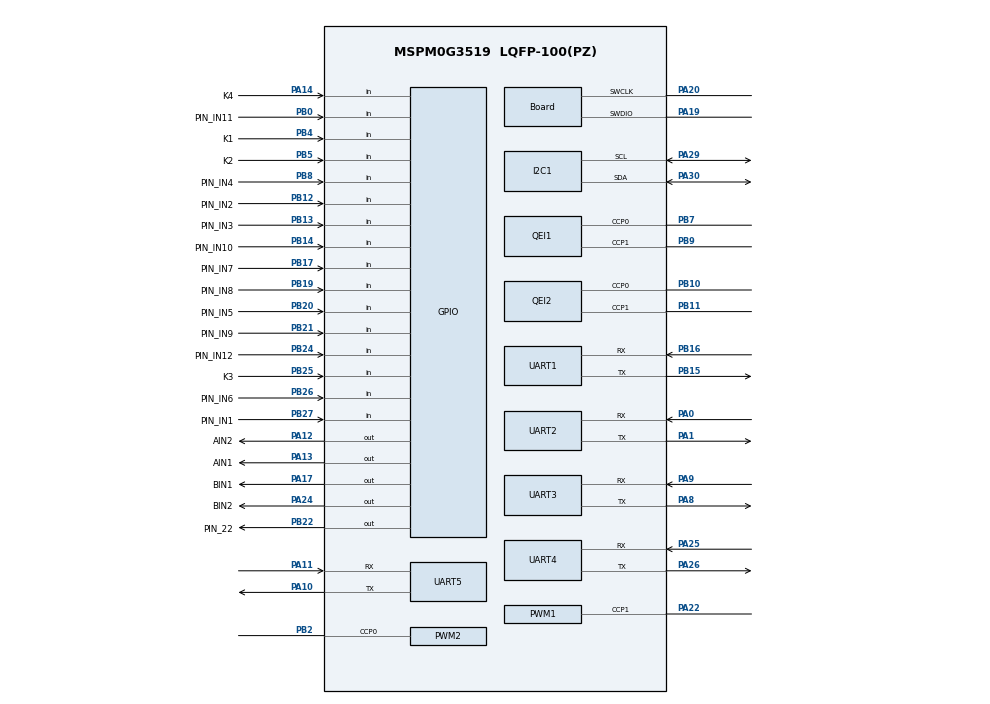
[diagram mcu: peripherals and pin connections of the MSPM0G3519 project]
/**
 * These arguments were used when this file was generated. They will be automatically applied on subsequent loads
 * via the GUI or CLI. Run CLI with '--help' for additional information on how to override these arguments.
 * @cliArgs --device "MSPM0G351X" --part "Default" --package "LQFP-100(PZ)" --product "mspm0_sdk@2.11.00.07"
 * @v2CliArgs --device "MSPM0G3519" --package "LQFP-100(PZ)" --product "mspm0_sdk@2.11.00.07"
 * @versions {"tool":"1.26.2+4477"}
 */

/**
 * Import the modules used in this configuration.
 */
const DMA    = scripting.addModule("/ti/driverlib/DMA");
const GPIO   = scripting.addModule("/ti/driverlib/GPIO", {}, false);
const GPIO1  = GPIO.addInstance();
const GPIO2  = GPIO.addInstance();
const GPIO3  = GPIO.addInstance();
const GPIO4  = GPIO.addInstance();
const I2C    = scripting.addModule("/ti/driverlib/I2C", {}, false);
const I2C1   = I2C.addInstance();
const PWM    = scripting.addModule("/ti/driverlib/PWM", {}, false);
const PWM1   = PWM.addInstance();
const PWM2   = PWM.addInstance();
const QEI    = scripting.addModule("/ti/driverlib/QEI", {}, false);
const QEI1   = QEI.addInstance();
const QEI2   = QEI.addInstance();
const SYSCTL = scripting.addModule("/ti/driverlib/SYSCTL");
const UART   = scripting.addModule("/ti/driverlib/UART", {}, false);
const UART1  = UART.addInstance();
const UART2  = UART.addInstance();
const UART3  = UART.addInstance();
const UART4  = UART.addInstance();
const UART5  = UART.addInstance();

/**
 * Write custom configuration values to the imported modules.
 */
const divider6       = system.clockTree["PLL_CLK2X_DIV"];
divider6.divideValue = 4;

const divider7       = system.clockTree["PLL_PDIV"];
divider7.divideValue = 2;

const divider9       = system.clockTree["UDIV"];
divider9.divideValue = 2;

const multiplier2         = system.clockTree["PLL_QDIV"];
multiplier2.multiplyValue = 10;

const mux8       = system.clockTree["HSCLKMUX"];
mux8.inputSelect = "HSCLKMUX_SYSPLL2X";

DMA.associatedChannels.create(1);
DMA.associatedChannels[0].$name              = "DMA_CH4";
DMA.associatedChannels[0].srcLength          = "BYTE";
DMA.associatedChannels[0].peripheral.$assign = "DMA_CH6";

const Board                       = scripting.addModule("/ti/driverlib/Board", {}, false);
Board.peripheral.$assign          = "DEBUGSS";
Board.peripheral.swclkPin.$assign = "PA20";
Board.peripheral.swdioPin.$assign = "PA19";

GPIO1.$name                              = "GPIO_GRP_KEY";
GPIO1.associatedPins.create(4);
GPIO1.associatedPins[0].$name            = "K1";
GPIO1.associatedPins[0].direction        = "INPUT";
GPIO1.associatedPins[0].internalResistor = "PULL_UP";
GPIO1.associatedPins[0].polarity         = "FALL";
GPIO1.associatedPins[0].interruptEn      = true;
GPIO1.associatedPins[0].pubChanID        = 1;
GPIO1.associatedPins[0].pin.$assign      = "PB4";
GPIO1.associatedPins[1].$name            = "K2";
GPIO1.associatedPins[1].direction        = "INPUT";
GPIO1.associatedPins[1].internalResistor = "PULL_UP";
GPIO1.associatedPins[1].polarity         = "FALL";
GPIO1.associatedPins[1].interruptEn      = true;
GPIO1.associatedPins[1].pubChanID        = 1;
GPIO1.associatedPins[1].pin.$assign      = "PB5";
GPIO1.associatedPins[2].$name            = "K3";
GPIO1.associatedPins[2].direction        = "INPUT";
GPIO1.associatedPins[2].internalResistor = "PULL_UP";
GPIO1.associatedPins[2].polarity         = "FALL";
GPIO1.associatedPins[2].interruptEn      = true;
GPIO1.associatedPins[2].pubChanID        = 1;
GPIO1.associatedPins[2].pin.$assign      = "PB25";
GPIO1.associatedPins[3].$name            = "K4";
GPIO1.associatedPins[3].direction        = "INPUT";
GPIO1.associatedPins[3].internalResistor = "PULL_UP";
GPIO1.associatedPins[3].polarity         = "FALL";
GPIO1.associatedPins[3].interruptEn      = true;
GPIO1.associatedPins[3].pubChanID        = 1;
GPIO1.associatedPins[3].pin.$assign      = "PA14";

/* 12 路灰度,物理排列从左到右 IN1 -> IN12(与旧版 Board_cfg 文档一致)。 */
/* GPIO_LINE_SENSOR = 12 路灰度循迹传感器。
 * ★ 12 路必须全部落在 PORTB，不得跨端口。原因：SysConfig 仅在同组同端口时生成
 *   组级单端口宏 GPIO_LINE_SENSOR_PORT，track_follow.c 依赖它一次读取全部 12 路；
 *   跨端口会使该宏消失（编译失败），且 12 路无法再原子采样，通道间产生时间偏斜。
 * 2026-07-16：IN4/IN5/IN10/IN11 让出 PB7/PB9/PB10/PB11 给编码器 QEI（编码器被核心板
 *   晶振逼出 PA 侧，且 QEI 只能落在特定 CCP 脚上；灰度是普通输入，落哪都行 ——
 *   约束多的先占位）。IN4 选 PB8 而非引脚表建议的 PA7：PB8 是 PB7 的物理邻脚，
 *   布线代价最小，且留在 PORTB。 */
GPIO2.$name                          = "GPIO_LINE_SENSOR";
GPIO2.associatedPins.create(12);
GPIO2.associatedPins[0].$name        = "PIN_IN1";
GPIO2.associatedPins[0].direction    = "INPUT";
GPIO2.associatedPins[0].pin.$assign  = "PB27";
GPIO2.associatedPins[1].$name        = "PIN_IN2";
GPIO2.associatedPins[1].direction    = "INPUT";
GPIO2.associatedPins[1].pin.$assign  = "PB12";
GPIO2.associatedPins[2].$name        = "PIN_IN3";
GPIO2.associatedPins[2].direction    = "INPUT";
GPIO2.associatedPins[2].pin.$assign  = "PB13";
GPIO2.associatedPins[3].$name        = "PIN_IN4";
GPIO2.associatedPins[3].direction    = "INPUT";
GPIO2.associatedPins[3].pin.$assign  = "PB8";
GPIO2.associatedPins[4].$name        = "PIN_IN5";
GPIO2.associatedPins[4].direction    = "INPUT";
GPIO2.associatedPins[4].pin.$assign  = "PB20";
GPIO2.associatedPins[5].$name        = "PIN_IN6";
GPIO2.associatedPins[5].direction    = "INPUT";
GPIO2.associatedPins[5].pin.$assign  = "PB26";
GPIO2.associatedPins[6].$name        = "PIN_IN7";
GPIO2.associatedPins[6].direction    = "INPUT";
GPIO2.associatedPins[6].pin.$assign  = "PB17";
GPIO2.associatedPins[7].$name        = "PIN_IN8";
GPIO2.associatedPins[7].direction    = "INPUT";
GPIO2.associatedPins[7].pin.$assign  = "PB19";
GPIO2.associatedPins[8].$name        = "PIN_IN9";
GPIO2.associatedPins[8].direction    = "INPUT";
GPIO2.associatedPins[8].pin.$assign  = "PB21";
GPIO2.associatedPins[9].$name        = "PIN_IN10";
GPIO2.associatedPins[9].direction    = "INPUT";
GPIO2.associatedPins[9].pin.$assign  = "PB14";
GPIO2.associatedPins[10].$name       = "PIN_IN11";
GPIO2.associatedPins[10].direction   = "INPUT";
GPIO2.associatedPins[10].pin.$assign = "PB0";
GPIO2.associatedPins[11].$name       = "PIN_IN12";
GPIO2.associatedPins[11].direction   = "INPUT";
GPIO2.associatedPins[11].pin.$assign = "PB24";

GPIO3.$name                         = "GPIO_DRIVE_DIR";
GPIO3.associatedPins.create(4);
GPIO3.associatedPins[0].$name       = "BIN1";
GPIO3.associatedPins[0].pin.$assign = "PA17";
GPIO3.associatedPins[1].$name       = "BIN2";
GPIO3.associatedPins[1].pin.$assign = "PA24";
GPIO3.associatedPins[2].$name       = "AIN1";
GPIO3.associatedPins[2].pin.$assign = "PA13";
GPIO3.associatedPins[3].$name       = "AIN2";
GPIO3.associatedPins[3].pin.$assign = "PA12";

GPIO4.port                               = "PORTB";
GPIO4.$name                              = "GPIO_STATUS_LED";
GPIO4.associatedPins[0].$name            = "PIN_22";
GPIO4.associatedPins[0].internalResistor = "PULL_DOWN";
GPIO4.associatedPins[0].pin.$assign      = "PB22";

I2C1.advAnalogGlitchFilter             = "DISABLED";
I2C1.basicEnableController             = true;
I2C1.basicControllerStandardBusSpeed   = "Fast";
I2C1.$name                             = "I2C_AUX";
I2C1.peripheral.$assign                = "I2C1";
I2C1.peripheral.sdaPin.$assign         = "PA30";
I2C1.peripheral.sclPin.$assign         = "PA29";
I2C1.sdaPinConfig.hideOutputInversion  = scripting.forceWrite(false);
I2C1.sdaPinConfig.onlyInternalResistor = scripting.forceWrite(false);
I2C1.sdaPinConfig.passedPeripheralType = scripting.forceWrite("Digital");
I2C1.sdaPinConfig.$name                = "ti_driverlib_gpio_GPIOPinGeneric4";
I2C1.sclPinConfig.hideOutputInversion  = scripting.forceWrite(false);
I2C1.sclPinConfig.onlyInternalResistor = scripting.forceWrite(false);
I2C1.sclPinConfig.passedPeripheralType = scripting.forceWrite("Digital");
I2C1.sclPinConfig.$name                = "ti_driverlib_gpio_GPIOPinGeneric5";

PWM1.ccIndex                            = [1];
PWM1.pwmMode                            = "EDGE_ALIGN_UP";
PWM1.timerCount                         = 7999;
PWM1.$name                              = "PWM_DRIVE_LEFT";
PWM1.ccp1PinConfig.direction            = scripting.forceWrite("OUTPUT");
PWM1.ccp1PinConfig.hideOutputInversion  = scripting.forceWrite(false);
PWM1.ccp1PinConfig.onlyInternalResistor = scripting.forceWrite(false);
PWM1.ccp1PinConfig.passedPeripheralType = scripting.forceWrite("Digital");
PWM1.ccp1PinConfig.$name                = "ti_driverlib_gpio_GPIOPinGeneric7";
PWM1.peripheral.$assign                 = "TIMA0";
PWM1.peripheral.ccp1Pin.$assign         = "PA22";
PWM1.PWM_CHANNEL_1.$name                = "ti_driverlib_pwm_PWMTimerCC1";

PWM2.ccIndex                            = [0];
PWM2.pwmMode                            = "EDGE_ALIGN_UP";
PWM2.timerCount                         = 7999;
PWM2.$name                              = "PWM_DRIVE_RIGHT";
PWM2.PWM_CHANNEL_0.$name                = "ti_driverlib_pwm_PWMTimerCC0";
PWM2.ccp0PinConfig.direction            = scripting.forceWrite("OUTPUT");
PWM2.ccp0PinConfig.hideOutputInversion  = scripting.forceWrite(false);
PWM2.ccp0PinConfig.onlyInternalResistor = scripting.forceWrite(false);
PWM2.ccp0PinConfig.passedPeripheralType = scripting.forceWrite("Digital");
PWM2.ccp0PinConfig.$name                = "ti_driverlib_gpio_GPIOPinGeneric8";
PWM2.peripheral.$assign                 = "TIMA1";
PWM2.peripheral.ccp0Pin.$assign         = "PB2";

/* QEI_LEFT = 左轮编码器。2026-07-16 迁出核心板晶振脚：
 * 原 PA7/PA6 中的 PA6 = SYSCTL.HFXOUT（高频晶振输出），核心板实焊晶振，不可作数字输入。
 * 迁至 PB7(A相)/PB9(B相)，二者是 TIMG9 的 CCP0/CCP1，故实例随之由 TIMG8 改 TIMG9。
 * $name 继续与物理左轮绑定，QEI_LEFT_INST 宏自动指向 TIMG9，encoder.c 无需感知。 */
QEI1.$name                              = "QEI_LEFT";
QEI1.peripheral.$assign                 = "TIMG9";
QEI1.peripheral.ccp0Pin.$assign         = "PB7";
QEI1.peripheral.ccp1Pin.$assign         = "PB9";
QEI1.ccp0PinConfig.hideOutputInversion  = scripting.forceWrite(false);
QEI1.ccp0PinConfig.onlyInternalResistor = scripting.forceWrite(false);
QEI1.ccp0PinConfig.passedPeripheralType = scripting.forceWrite("Digital");
QEI1.ccp0PinConfig.$name                = "ti_driverlib_gpio_GPIOPinGeneric14";
QEI1.ccp1PinConfig.hideOutputInversion  = scripting.forceWrite(false);
QEI1.ccp1PinConfig.onlyInternalResistor = scripting.forceWrite(false);
QEI1.ccp1PinConfig.passedPeripheralType = scripting.forceWrite("Digital");
QEI1.ccp1PinConfig.$name                = "ti_driverlib_gpio_GPIOPinGeneric15";

/* QEI_RIGHT = 右轮编码器。2026-07-16 迁出核心板晶振脚：
 * 原 PA3 = SYSCTL.LFXIN（低频晶振输入）、PA2 = SYSCTL.ROSC（振荡器外接电阻），均不可作数字输入。
 * 迁至 PB10(A相)/PB11(B相)，二者是 TIMG8 的 CCP0/CCP1，故实例随之由 TIMG9 改 TIMG8。
 * 与 QEI_LEFT 的 timer 归属互换，但左右语义由 $name 承载，不产生静默对调。 */
QEI2.$name                              = "QEI_RIGHT";
QEI2.peripheral.$assign                 = "TIMG8";
QEI2.peripheral.ccp0Pin.$assign         = "PB10";
QEI2.peripheral.ccp1Pin.$assign         = "PB11";
QEI2.ccp0PinConfig.hideOutputInversion  = scripting.forceWrite(false);
QEI2.ccp0PinConfig.onlyInternalResistor = scripting.forceWrite(false);
QEI2.ccp0PinConfig.passedPeripheralType = scripting.forceWrite("Digital");
QEI2.ccp0PinConfig.$name                = "ti_driverlib_gpio_GPIOPinGeneric16";
QEI2.ccp1PinConfig.hideOutputInversion  = scripting.forceWrite(false);
QEI2.ccp1PinConfig.onlyInternalResistor = scripting.forceWrite(false);
QEI2.ccp1PinConfig.passedPeripheralType = scripting.forceWrite("Digital");
QEI2.ccp1PinConfig.$name                = "ti_driverlib_gpio_GPIOPinGeneric17";

SYSCTL.forceDefaultClkConfig = true;
SYSCTL.clockTreeEn           = true;

UART1.enableFIFO                        = true;
UART1.enabledInterrupts                 = ["DMA_DONE_RX"];
UART1.enabledDMARXTriggers              = "DL_UART_DMA_INTERRUPT_RX";
UART1.enabledDMATXTriggers              = "DL_UART_DMA_INTERRUPT_TX";
UART1.targetBaudRate                    = 230400;
UART1.$name                             = "UART_STEPPER_BUS";
UART1.peripheral.$assign                = "UART7";
UART1.peripheral.rxPin.$assign          = "PB16";
UART1.peripheral.txPin.$assign          = "PB15";
UART1.txPinConfig.direction             = scripting.forceWrite("OUTPUT");
UART1.txPinConfig.hideOutputInversion   = scripting.forceWrite(false);
UART1.txPinConfig.onlyInternalResistor  = scripting.forceWrite(false);
UART1.txPinConfig.passedPeripheralType  = scripting.forceWrite("Digital");
UART1.txPinConfig.$name                 = "ti_driverlib_gpio_GPIOPinGeneric0";
UART1.rxPinConfig.hideOutputInversion   = scripting.forceWrite(false);
UART1.rxPinConfig.onlyInternalResistor  = scripting.forceWrite(false);
UART1.rxPinConfig.passedPeripheralType  = scripting.forceWrite("Digital");
UART1.rxPinConfig.$name                 = "ti_driverlib_gpio_GPIOPinGeneric1";
UART1.DMA_CHANNEL_RX.$name              = "DMA_CH0";
UART1.DMA_CHANNEL_RX.addressMode        = "f2b";
UART1.DMA_CHANNEL_RX.srcLength          = "BYTE";
UART1.DMA_CHANNEL_RX.dstLength          = "BYTE";
UART1.DMA_CHANNEL_RX.destIncrement      = "INCREMENT";
UART1.DMA_CHANNEL_RX.transferSize       = 64;
UART1.DMA_CHANNEL_RX.enableInterrupt    = true;
UART1.DMA_CHANNEL_RX.peripheral.$assign = "DMA_CH0";
UART1.DMA_CHANNEL_TX.enableInterrupt    = true;
UART1.DMA_CHANNEL_TX.addressMode        = "b2f";
UART1.DMA_CHANNEL_TX.srcLength          = "BYTE";
UART1.DMA_CHANNEL_TX.dstLength          = "BYTE";
UART1.DMA_CHANNEL_TX.$name              = "DMA_CH3";
UART1.DMA_CHANNEL_TX.peripheral.$assign = "DMA_CH3";
scripting.suppress("Destination Increment is controlled by the Destination Address Direction configurable\\.", UART1.DMA_CHANNEL_RX, "dstIncDec");

/* UART_HOST_LINK = VOFA 上下位机实时调参链路（脚本变量 UART2 → 物理外设 UART5）。
 * 2026-07-16 由 UART0/PA10/PA11 迁出：PA10/PA11 交还 BSL 烧录专用（见下方 UART5 块）。
 * $name 与两个 DMA 通道 $name 必须保持不变——driver 全部引用生成宏
 * UART_HOST_LINK_INST / DMA_CH1_CHAN_ID，改名即需改代码。 */
UART2.enableFIFO                        = true;
UART2.enabledDMATXTriggers              = "DL_UART_DMA_INTERRUPT_TX";
UART2.enabledDMARXTriggers              = "DL_UART_DMA_INTERRUPT_RX";
UART2.enabledInterrupts                 = ["DMA_DONE_RX","DMA_DONE_TX"];
UART2.targetBaudRate                    = 230400;
UART2.$name                             = "UART_HOST_LINK";
UART2.peripheral.$assign                = "UART5";
UART2.peripheral.rxPin.$assign          = "PA0";
UART2.peripheral.txPin.$assign          = "PA1";
UART2.txPinConfig.direction             = scripting.forceWrite("OUTPUT");
UART2.txPinConfig.hideOutputInversion   = scripting.forceWrite(false);
UART2.txPinConfig.onlyInternalResistor  = scripting.forceWrite(false);
UART2.txPinConfig.passedPeripheralType  = scripting.forceWrite("Digital");
UART2.txPinConfig.$name                 = "ti_driverlib_gpio_GPIOPinGeneric2";
UART2.rxPinConfig.hideOutputInversion   = scripting.forceWrite(false);
UART2.rxPinConfig.onlyInternalResistor  = scripting.forceWrite(false);
UART2.rxPinConfig.passedPeripheralType  = scripting.forceWrite("Digital");
UART2.rxPinConfig.$name                 = "ti_driverlib_gpio_GPIOPinGeneric3";
UART2.DMA_CHANNEL_TX.$name              = "DMA_CH1";
UART2.DMA_CHANNEL_TX.addressMode        = "b2f";
UART2.DMA_CHANNEL_TX.srcLength          = "BYTE";
UART2.DMA_CHANNEL_TX.dstLength          = "BYTE";
UART2.DMA_CHANNEL_TX.srcIncrement       = "INCREMENT";
UART2.DMA_CHANNEL_TX.enableInterrupt    = true;
UART2.DMA_CHANNEL_TX.peripheral.$assign = "DMA_CH4";
UART2.DMA_CHANNEL_RX.$name              = "DMA_CH2";
UART2.DMA_CHANNEL_RX.addressMode        = "f2b";
UART2.DMA_CHANNEL_RX.srcLength          = "BYTE";
UART2.DMA_CHANNEL_RX.dstLength          = "BYTE";
UART2.DMA_CHANNEL_RX.enableInterrupt    = true;
UART2.DMA_CHANNEL_RX.peripheral.$assign = "DMA_CH2";
scripting.suppress("Source Increment is controlled by the Source Address Direction configurable\\.", UART2.DMA_CHANNEL_TX, "srcIncDec");

UART3.enableFIFO                        = true;
UART3.enabledDMATXTriggers              = "DL_UART_DMA_INTERRUPT_TX";
UART3.enabledDMARXTriggers              = "DL_UART_DMA_INTERRUPT_RX";
UART3.enabledInterrupts                 = ["DMA_DONE_RX","DMA_DONE_TX"];
UART3.targetBaudRate                    = 230400;
UART3.$name                             = "UART_VISION";
UART3.peripheral.$assign                = "UART1";
UART3.peripheral.rxPin.$assign          = "PA9";
UART3.peripheral.txPin.$assign          = "PA8";
UART3.txPinConfig.direction             = scripting.forceWrite("OUTPUT");
UART3.txPinConfig.hideOutputInversion   = scripting.forceWrite(false);
UART3.txPinConfig.onlyInternalResistor  = scripting.forceWrite(false);
UART3.txPinConfig.passedPeripheralType  = scripting.forceWrite("Digital");
UART3.txPinConfig.$name                 = "ti_driverlib_gpio_GPIOPinGeneric6";
UART3.rxPinConfig.hideOutputInversion   = scripting.forceWrite(false);
UART3.rxPinConfig.onlyInternalResistor  = scripting.forceWrite(false);
UART3.rxPinConfig.passedPeripheralType  = scripting.forceWrite("Digital");
UART3.rxPinConfig.$name                 = "ti_driverlib_gpio_GPIOPinGeneric9";
UART3.DMA_CHANNEL_TX.addressMode        = "b2f";
UART3.DMA_CHANNEL_TX.srcLength          = "BYTE";
UART3.DMA_CHANNEL_TX.dstLength          = "BYTE";
UART3.DMA_CHANNEL_TX.srcIncrement       = "INCREMENT";
UART3.DMA_CHANNEL_TX.enableInterrupt    = true;
UART3.DMA_CHANNEL_TX.$name              = "DMA_CH8";
UART3.DMA_CHANNEL_TX.peripheral.$assign = "DMA_CH5";
UART3.DMA_CHANNEL_RX.$name              = "DMA_CH7";
UART3.DMA_CHANNEL_RX.addressMode        = "f2b";
UART3.DMA_CHANNEL_RX.srcLength          = "BYTE";
UART3.DMA_CHANNEL_RX.dstLength          = "BYTE";
UART3.DMA_CHANNEL_RX.enableInterrupt    = true;
UART3.DMA_CHANNEL_RX.peripheral.$assign = "DMA_CH1";
scripting.suppress("Source Increment is controlled by the Source Address Direction configurable\\.", UART3.DMA_CHANNEL_TX, "srcIncDec");

UART4.$name                            = "UART_IMU";
UART4.targetBaudRate                   = 230400;
UART4.enableFIFO                       = true;
UART4.rxFifoThreshold                  = "DL_UART_RX_FIFO_LEVEL_FULL";
UART4.txFifoThreshold                  = "DL_UART_TX_FIFO_LEVEL_1_4_EMPTY";
UART4.peripheral.$assign               = "UART3";
UART4.peripheral.rxPin.$assign         = "PA25";
UART4.peripheral.txPin.$assign         = "PA26";
UART4.txPinConfig.direction            = scripting.forceWrite("OUTPUT");
UART4.txPinConfig.hideOutputInversion  = scripting.forceWrite(false);
UART4.txPinConfig.onlyInternalResistor = scripting.forceWrite(false);
UART4.txPinConfig.passedPeripheralType = scripting.forceWrite("Digital");
UART4.txPinConfig.$name                = "ti_driverlib_gpio_GPIOPinGeneric12";
UART4.rxPinConfig.hideOutputInversion  = scripting.forceWrite(false);
UART4.rxPinConfig.onlyInternalResistor = scripting.forceWrite(false);
UART4.rxPinConfig.passedPeripheralType = scripting.forceWrite("Digital");
UART4.rxPinConfig.$name                = "ti_driverlib_gpio_GPIOPinGeneric13";

/* UART_BSL_ENTRY = 无线 BSL 烧录口（脚本变量 UART5 → 物理外设 UART0）。
 * 波特率 9600 是 ROM BSL 的固定值，非可调项：SDK bsl_uart_flash_interface
 * 定义 BSL_UART_DEFAULT_BAUD=9600，且 TI 的 BSL GUI 把 baudrate=9600 写死。
 * PA10/PA11 亦为 ROM BSL 固定引脚。
 *
 * 无 DMA、无中断：本口运行期只需接收上位机的 ENTRY 字节 0x22 触发软件跳
 * BSL（参考 SDK bsl_software_invoke_app_demo_uart），单字节事件不值得占用
 * DMA 通道。中断待 ENTRY 监听器落地时再开——现在开了却没有 IRQ handler，
 * 首个到达字节就会落进 startup 的默认处理程序死循环。 */
UART5.$name                            = "UART_BSL_ENTRY";
UART5.targetBaudRate                   = 9600;
UART5.enableFIFO                       = true;
UART5.peripheral.$assign               = "UART0";
UART5.peripheral.rxPin.$assign         = "PA11";
UART5.peripheral.txPin.$assign         = "PA10";
UART5.txPinConfig.direction            = scripting.forceWrite("OUTPUT");
UART5.txPinConfig.hideOutputInversion  = scripting.forceWrite(false);
UART5.txPinConfig.onlyInternalResistor = scripting.forceWrite(false);
UART5.txPinConfig.passedPeripheralType = scripting.forceWrite("Digital");
UART5.txPinConfig.$name                = "ti_driverlib_gpio_GPIOPinGeneric18";
UART5.rxPinConfig.hideOutputInversion  = scripting.forceWrite(false);
UART5.rxPinConfig.onlyInternalResistor = scripting.forceWrite(false);
UART5.rxPinConfig.passedPeripheralType = scripting.forceWrite("Digital");
UART5.rxPinConfig.$name                = "ti_driverlib_gpio_GPIOPinGeneric19";
